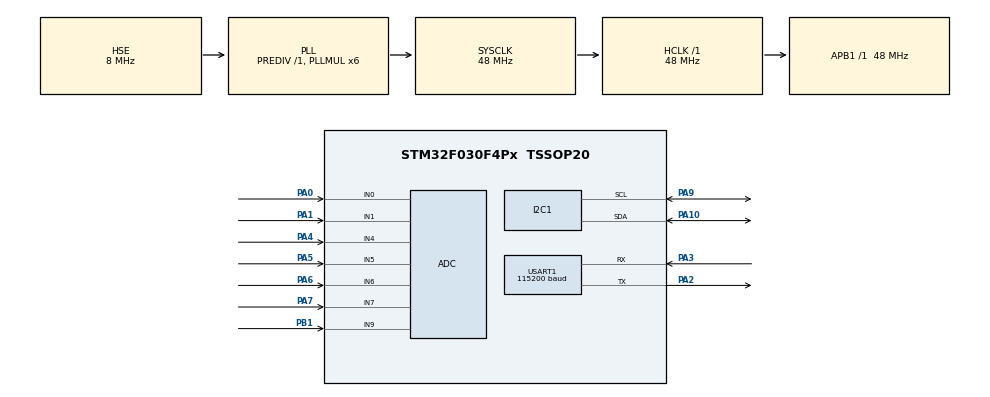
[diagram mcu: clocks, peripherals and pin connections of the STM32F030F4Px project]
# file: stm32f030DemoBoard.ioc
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I2C1.Timing=0x20303E5D
Mcu.Family=STM32F0
Mcu.Name=STM32F030F4Px
Mcu.Package=TSSOP20
NVIC.TIM1_BRK_UP_TRG_COM_IRQn=true\:0\:0\:false\:false\:true\:false
NVIC.TimeBase=TIM1_BRK_UP_TRG_COM_IRQn
NVIC.TimeBaseIP=TIM1
PA0.Mode=IN0
PA0.Signal=ADC_IN0
PA1.Mode=IN1
PA1.Signal=ADC_IN1
PA10.GPIO_FMA10=SYSCFG_CFGR1_I2C_FMP_PA10
PA10.Mode=I2C
PA10.Signal=I2C1_SDA
PA13.Mode=Serial_Wire
PA13.Signal=SYS_SWDIO
PA14.Mode=Serial_Wire
PA14.Signal=SYS_SWCLK
PA2.Mode=Asynchronous
PA2.Signal=USART1_TX
PA3.Mode=Asynchronous
PA3.Signal=USART1_RX
PA4.Mode=IN4
PA4.Signal=ADC_IN4
PA5.Mode=IN5
PA5.Signal=ADC_IN5
PA6.Mode=IN6
PA6.Signal=ADC_IN6
PA7.Mode=IN7
PA7.Signal=ADC_IN7
PA9.GPIO_FMA9=SYSCFG_CFGR1_I2C_FMP_PA9
PA9.Mode=I2C
PA9.Signal=I2C1_SCL
PB1.Mode=IN9
PB1.Signal=ADC_IN9
PF0-OSC_IN.Mode=HSE-External-Oscillator
PF0-OSC_IN.Signal=RCC_OSC_IN
PF1-OSC_OUT.Mode=HSE-External-Oscillator
PF1-OSC_OUT.Signal=RCC_OSC_OUT
ProjectManager.HeapSize=0x200
ProjectManager.StackSize=0x400
ProjectManager.TargetToolchain=MDK-ARM V5
RCC.AHBFreq_Value=48000000
RCC.APB1Freq_Value=48000000
RCC.APB1TimFreq_Value=48000000
RCC.HCLKFreq_Value=48000000
RCC.I2c1ClockSelection=RCC_I2C1CLKSOURCE_SYSCLK
RCC.PLLMUL=RCC_PLL_MUL6
RCC.PLLSourceVirtual=RCC_PLLSOURCE_HSE
RCC.SYSCLKFreq_VALUE=48000000
RCC.SYSCLKSource=RCC_SYSCLKSOURCE_PLLCLK
USART1.BaudRate=115200
USART1.VirtualMode-Asynchronous=VM_ASYNC
VP_ADC_TempSens_Input.Mode=IN-TempSens
VP_ADC_Vref_Input.Mode=IN-Vrefint
VP_RTC_VS_RTC_Activate.Mode=RTC_Enabled
VP_RTC_VS_RTC_Calendar.Mode=RTC_Calendar
VP_SYS_VS_tim1.Mode=TIM1
board=custom

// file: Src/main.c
/**
  ******************************************************************************
  * @file           : main.c
  * @brief          : Main program body
  ******************************************************************************
  ** This notice applies to any and all portions of this file
  * that are not between comment pairs USER CODE BEGIN and
  * USER CODE END. Other portions of this file, whether
  * inserted by the user or by software development tools
  * are owned by their respective copyright owners.
  *
  * COPYRIGHT(c) 2018 STMicroelectronics
  *
  * Redistribution and use in source and binary forms, with or without modification,
  * are permitted provided that the following conditions are met:
  *   1. Redistributions of source code must retain the above copyright notice,
  *      this list of conditions and the following disclaimer.
  *   2. Redistributions in binary form must reproduce the above copyright notice,
  *      this list of conditions and the following disclaimer in the documentation
  *      and/or other materials provided with the distribution.
  *   3. Neither the name of STMicroelectronics nor the names of its contributors
  *      may be used to endorse or promote products derived from this software
  *      without specific prior written permission.
  *
  * THIS SOFTWARE IS PROVIDED BY THE COPYRIGHT HOLDERS AND CONTRIBUTORS "AS IS"
  * AND ANY EXPRESS OR IMPLIED WARRANTIES, INCLUDING, BUT NOT LIMITED TO, THE
  * IMPLIED WARRANTIES OF MERCHANTABILITY AND FITNESS FOR A PARTICULAR PURPOSE ARE
  * DISCLAIMED. IN NO EVENT SHALL THE COPYRIGHT HOLDER OR CONTRIBUTORS BE LIABLE
  * FOR ANY DIRECT, INDIRECT, INCIDENTAL, SPECIAL, EXEMPLARY, OR CONSEQUENTIAL
  * DAMAGES (INCLUDING, BUT NOT LIMITED TO, PROCUREMENT OF SUBSTITUTE GOODS OR
  * SERVICES; LOSS OF USE, DATA, OR PROFITS; OR BUSINESS INTERRUPTION) HOWEVER
  * CAUSED AND ON ANY THEORY OF LIABILITY, WHETHER IN CONTRACT, STRICT LIABILITY,
  * OR TORT (INCLUDING NEGLIGENCE OR OTHERWISE) ARISING IN ANY WAY OUT OF THE USE
  * OF THIS SOFTWARE, EVEN IF ADVISED OF THE POSSIBILITY OF SUCH DAMAGE.
  *
  ******************************************************************************
  */
#include "main.h"
#include "stm32f0xx_hal.h"
// #include "bme280_mod.h"

ADC_HandleTypeDef hadc;
RTC_HandleTypeDef hrtc;
I2C_HandleTypeDef hi2c1;
UART_HandleTypeDef huart1;

/* USER CODE BEGIN PV */
/* Private variables ---------------------------------------------------------*/

#define I2C_ADDRESS (0x76<<1) //  (0x60<<1)
#define IMU_WHO_AM_I 0xC
/* USER CODE END PV */

void SystemClock_Config(void);
static void MX_GPIO_Init(void);
static void MX_I2C1_Init(void);
static void MX_ADC_Init(void);
static void MX_USART1_UART_Init(void);
static void MX_RTC_Init(void);
static void mpl3115a(void);
/* USER CODE BEGIN PFP */
void delay (int a);

int main(void)
{
  HAL_Init();
  SystemClock_Config();
  MX_ADC_Init();
  MX_GPIO_Init();
  MX_USART1_UART_Init();
  MX_RTC_Init();
  MX_I2C1_Init();

	uint8_t reg=0xF7; // pres + temp registers
	I2C_HandleTypeDef hi2c = hi2c1;
	uint16_t DevAddress = I2C_ADDRESS;
	uint16_t MemAddress = 0xf4;// configuration registers 0xf4, 0xf5
	uint16_t MemAddSize = 1;
	uint8_t pData[2] = {0xff,0x10};
	//pData[0] = 3;
	uint16_t Size = 2;
	uint32_t Timeout = 100;
	while(HAL_I2C_IsDeviceReady(&hi2c1, DevAddress, 1, HAL_MAX_DELAY)!=HAL_OK);
	HAL_I2C_Mem_Write(&hi2c, DevAddress, MemAddress, MemAddSize, pData, Size, Timeout);
	while (1)
  {
		HAL_ADC_Start(&hadc);

		HAL_GPIO_WritePin(GPIOA,GPIO_PIN_4,GPIO_PIN_SET);//LED on
		HAL_Delay(50);
		HAL_GPIO_WritePin(GPIOA,GPIO_PIN_4,GPIO_PIN_RESET);//LED off
		if(0) mpl3115a();
		//uint8_t analog0 = HAL_AD
		uint8_t temp[]={0,0,0,0,0,0};
	  while(HAL_I2C_IsDeviceReady(&hi2c1, DevAddress, 1, HAL_MAX_DELAY)!=HAL_OK);
		HAL_I2C_Mem_Read(&hi2c1,I2C_ADDRESS,reg,1,temp,sizeof(temp),1000);
		uint16_t x[] = {0};
		if(HAL_ADC_PollForConversion(&hadc,100)!=HAL_ERROR)
			x[0] = HAL_ADC_GetValue(&hadc);
		for(int j=0; j<sizeof(temp);j++){
				HAL_UART_Transmit(&huart1,&(temp[j]),sizeof(temp[j]),100);
		}
		HAL_ADC_Stop(&hadc);

		//HAL_UART_Transmit(&huart1,(uint8_t *)(x),sizeof(x),100);
		HAL_Delay(20);
		//delay(200000);
  }
}
void mpl3115a(void){	// ------ i2c Polling - no FIFO
		uint8_t reg = 0x0C; //  1. who am i?
		uint8_t val[] = {0,0,0,0,0,0,0};
		while(HAL_I2C_IsDeviceReady(&hi2c1, I2C_ADDRESS, 1, HAL_MAX_DELAY)!=HAL_OK) ;
		HAL_I2C_Mem_Read(&hi2c1, I2C_ADDRESS, reg, I2C_MEMADD_SIZE_8BIT, val, 2, HAL_MAX_DELAY);
		delay(100000);
		while(HAL_I2C_IsDeviceReady(&hi2c1, I2C_ADDRESS, 1, HAL_MAX_DELAY)!=HAL_OK);
		if(1){
			HAL_UART_Transmit(&huart1,&val[0],sizeof(val),1000);
			HAL_UART_Transmit(&huart1,(uint8_t *)"\r\n",sizeof("\r\n"),1000);
		}

		reg = 0x26; //  2. Altimeter to OSR = 128
		uint8_t write[] = {0xB8};
		while(HAL_I2C_IsDeviceReady(&hi2c1, I2C_ADDRESS, 1, HAL_MAX_DELAY)!=HAL_OK);
		HAL_I2C_Mem_Write(&hi2c1, I2C_ADDRESS, reg, I2C_MEMADD_SIZE_8BIT, write, 2, HAL_MAX_DELAY);
		while(HAL_I2C_IsDeviceReady(&hi2c1, I2C_ADDRESS, 1, HAL_MAX_DELAY)!=HAL_OK);

		reg = 0x13; //  3. Enable data flags in PT_DATA_CFG
		write[0] = 0x07;
		while(HAL_I2C_IsDeviceReady(&hi2c1, I2C_ADDRESS, 1, HAL_MAX_DELAY)!=HAL_OK);
		HAL_I2C_Mem_Write(&hi2c1, I2C_ADDRESS, reg, I2C_MEMADD_SIZE_8BIT, write, 2, HAL_MAX_DELAY);
		while(HAL_I2C_IsDeviceReady(&hi2c1, I2C_ADDRESS, 1, HAL_MAX_DELAY)!=HAL_OK);

		reg = 0x26; //  4. Set active
		write[0] = 0xB9;
		while(HAL_I2C_IsDeviceReady(&hi2c1, I2C_ADDRESS, 1, HAL_MAX_DELAY)!=HAL_OK);
		HAL_I2C_Mem_Write(&hi2c1, I2C_ADDRESS, reg, I2C_MEMADD_SIZE_8BIT, write, 2, HAL_MAX_DELAY);
		while(HAL_I2C_IsDeviceReady(&hi2c1, I2C_ADDRESS, 1, HAL_MAX_DELAY)!=HAL_OK);

		while(1){
			val[0]=0;
			reg = 0x0; //  5. Read Status Register + DATA
			// while(HAL_I2C_IsDeviceReady(&hi2c1, I2C_ADDRESS, 1, HAL_MAX_DELAY)!=HAL_OK);
			while(val[0]==0)
				HAL_I2C_Mem_Read(&hi2c1, I2C_ADDRESS, 0x0, I2C_MEMADD_SIZE_8BIT, val, 6, HAL_MAX_DELAY);
			HAL_UART_Transmit(&huart1,val,sizeof(val),1000);
			HAL_UART_Transmit(&huart1,(uint8_t *)"\r\n",sizeof("\r\n"),1000);
			delay(480000);
		}
}
void SystemClock_Config(void)
{

  RCC_OscInitTypeDef RCC_OscInitStruct;
  RCC_ClkInitTypeDef RCC_ClkInitStruct;
  RCC_PeriphCLKInitTypeDef PeriphClkInit;

    /**Initializes the CPU, AHB and APB busses clocks
    */
  RCC_OscInitStruct.OscillatorType = RCC_OSCILLATORTYPE_HSI14|RCC_OSCILLATORTYPE_LSI
                              |RCC_OSCILLATORTYPE_HSE;
  RCC_OscInitStruct.HSEState = RCC_HSE_ON;
  RCC_OscInitStruct.HSI14State = RCC_HSI14_ON;
  RCC_OscInitStruct.HSI14CalibrationValue = 16;
  RCC_OscInitStruct.LSIState = RCC_LSI_ON;
  RCC_OscInitStruct.PLL.PLLState = RCC_PLL_ON;
  RCC_OscInitStruct.PLL.PLLSource = RCC_PLLSOURCE_HSE;
  RCC_OscInitStruct.PLL.PLLMUL = RCC_PLL_MUL6;
  RCC_OscInitStruct.PLL.PREDIV = RCC_PREDIV_DIV1;
  if (HAL_RCC_OscConfig(&RCC_OscInitStruct) != HAL_OK)
  {
    _Error_Handler(__FILE__, __LINE__);
  }

    /**Initializes the CPU, AHB and APB busses clocks
    */
  RCC_ClkInitStruct.ClockType = RCC_CLOCKTYPE_HCLK|RCC_CLOCKTYPE_SYSCLK
                              |RCC_CLOCKTYPE_PCLK1;
  RCC_ClkInitStruct.SYSCLKSource = RCC_SYSCLKSOURCE_PLLCLK;
  RCC_ClkInitStruct.AHBCLKDivider = RCC_SYSCLK_DIV1;
  RCC_ClkInitStruct.APB1CLKDivider = RCC_HCLK_DIV1;

  if (HAL_RCC_ClockConfig(&RCC_ClkInitStruct, FLASH_LATENCY_1) != HAL_OK)
  {
    _Error_Handler(__FILE__, __LINE__);
  }

  PeriphClkInit.PeriphClockSelection = RCC_PERIPHCLK_USART1|RCC_PERIPHCLK_I2C1
                              |RCC_PERIPHCLK_RTC;
  PeriphClkInit.Usart1ClockSelection = RCC_USART1CLKSOURCE_PCLK1;
  PeriphClkInit.I2c1ClockSelection = RCC_I2C1CLKSOURCE_SYSCLK;
  PeriphClkInit.RTCClockSelection = RCC_RTCCLKSOURCE_LSI;
  if (HAL_RCCEx_PeriphCLKConfig(&PeriphClkInit) != HAL_OK)
  {
    _Error_Handler(__FILE__, __LINE__);
  }

    /**Configure the Systick interrupt time
    */
  HAL_SYSTICK_Config(HAL_RCC_GetHCLKFreq()/1000);

    /**Configure the Systick
    */
  HAL_SYSTICK_CLKSourceConfig(SYSTICK_CLKSOURCE_HCLK);

  /* SysTick_IRQn interrupt configuration */
  HAL_NVIC_SetPriority(SysTick_IRQn, 0, 0);
}

/* ADC init function */
static void MX_ADC_Init(void)
{

  ADC_ChannelConfTypeDef sConfig;

    /**Configure the global features of the ADC (Clock, Resolution, Data Alignment and number of conversion)
    */
  hadc.Instance = ADC1;
  hadc.Init.ClockPrescaler = ADC_CLOCK_ASYNC_DIV1;
  hadc.Init.Resolution = ADC_RESOLUTION_12B;
  hadc.Init.DataAlign = ADC_DATAALIGN_RIGHT;
  hadc.Init.ScanConvMode = ADC_SCAN_DIRECTION_FORWARD;
  hadc.Init.EOCSelection = DISABLE;
  hadc.Init.LowPowerAutoWait = DISABLE;
  hadc.Init.LowPowerAutoPowerOff = DISABLE;
  hadc.Init.ContinuousConvMode = DISABLE;
  hadc.Init.DiscontinuousConvMode = DISABLE;
  hadc.Init.ExternalTrigConv = ADC_SOFTWARE_START;
  hadc.Init.ExternalTrigConvEdge = ADC_EXTERNALTRIGCONVEDGE_NONE;
  hadc.Init.DMAContinuousRequests = DISABLE;
  hadc.Init.Overrun = ADC_OVR_DATA_PRESERVED;
  if (HAL_ADC_Init(&hadc) != HAL_OK)
  {
    _Error_Handler(__FILE__, __LINE__);
  }

    /**Configure for the selected ADC regular channel to be converted.
    */
  sConfig.Channel = ADC_CHANNEL_0;
  sConfig.Rank = ADC_RANK_CHANNEL_NUMBER;
  sConfig.SamplingTime = ADC_SAMPLETIME_1CYCLE_5;
  if (HAL_ADC_ConfigChannel(&hadc, &sConfig) != HAL_OK)
  {
    _Error_Handler(__FILE__, __LINE__);
  }

    /**Configure for the selected ADC regular channel to be converted.
    */
  sConfig.Channel = ADC_CHANNEL_1;
  if (HAL_ADC_ConfigChannel(&hadc, &sConfig) != HAL_OK)
  {
    _Error_Handler(__FILE__, __LINE__);
  }

    /**Configure for the selected ADC regular channel to be converted.
    */
//  sConfig.Channel = ADC_CHANNEL_4;
//  if (HAL_ADC_ConfigChannel(&hadc, &sConfig) != HAL_OK)
//  {
//    _Error_Handler(__FILE__, __LINE__);
//  }

    /**Configure for the selected ADC regular channel to be converted.
    */
  sConfig.Channel = ADC_CHANNEL_5;
  if (HAL_ADC_ConfigChannel(&hadc, &sConfig) != HAL_OK)
  {
    _Error_Handler(__FILE__, __LINE__);
  }

    /**Configure for the selected ADC regular channel to be converted.
    */
  sConfig.Channel = ADC_CHANNEL_6;
  if (HAL_ADC_ConfigChannel(&hadc, &sConfig) != HAL_OK)
  {
    _Error_Handler(__FILE__, __LINE__);
  }

    /**Configure for the selected ADC regular channel to be converted.
    */
  sConfig.Channel = ADC_CHANNEL_7;
  if (HAL_ADC_ConfigChannel(&hadc, &sConfig) != HAL_OK)
  {
    _Error_Handler(__FILE__, __LINE__);
  }

    /**Configure for the selected ADC regular channel to be converted.
    */
  sConfig.Channel = ADC_CHANNEL_9;
  if (HAL_ADC_ConfigChannel(&hadc, &sConfig) != HAL_OK)
  {
    _Error_Handler(__FILE__, __LINE__);
  }

    /**Configure for the selected ADC regular channel to be converted.
    */
  sConfig.Channel = ADC_CHANNEL_TEMPSENSOR;
  if (HAL_ADC_ConfigChannel(&hadc, &sConfig) != HAL_OK)
  {
    _Error_Handler(__FILE__, __LINE__);
  }

    /**Configure for the selected ADC regular channel to be converted.
    */
  sConfig.Channel = ADC_CHANNEL_VREFINT;
  if (HAL_ADC_ConfigChannel(&hadc, &sConfig) != HAL_OK)
  {
    _Error_Handler(__FILE__, __LINE__);
  }

}

/* I2C1 init function */
static void MX_I2C1_Init(void)
{

  hi2c1.Instance = I2C1;
  hi2c1.Init.Timing = 0x1303E5D; // 0x20303E5D
  hi2c1.Init.OwnAddress1 = 0;
  hi2c1.Init.AddressingMode = I2C_ADDRESSINGMODE_7BIT;
  hi2c1.Init.DualAddressMode = I2C_DUALADDRESS_DISABLE;
  hi2c1.Init.OwnAddress2 = 0;
  hi2c1.Init.OwnAddress2Masks = I2C_OA2_NOMASK;
  hi2c1.Init.GeneralCallMode = I2C_GENERALCALL_DISABLE;
  hi2c1.Init.NoStretchMode = I2C_NOSTRETCH_DISABLE;
  if (HAL_I2C_Init(&hi2c1) != HAL_OK)
  {
    _Error_Handler(__FILE__, __LINE__);
  }

    /**Configure Analogue filter
    */
  if (HAL_I2CEx_ConfigAnalogFilter(&hi2c1, I2C_ANALOGFILTER_ENABLE) != HAL_OK)
  {
    _Error_Handler(__FILE__, __LINE__);
  }

    /**Configure Digital filter
    */
  if (HAL_I2CEx_ConfigDigitalFilter(&hi2c1, 0) != HAL_OK)
  {
    _Error_Handler(__FILE__, __LINE__);
  }

}

/* RTC init function */
static void MX_RTC_Init(void)
{

  RTC_TimeTypeDef sTime;
  RTC_DateTypeDef sDate;

    /**Initialize RTC Only
    */
  hrtc.Instance = RTC;
  hrtc.Init.HourFormat = RTC_HOURFORMAT_24;
  hrtc.Init.AsynchPrediv = 127;
  hrtc.Init.SynchPrediv = 255;
  hrtc.Init.OutPut = RTC_OUTPUT_DISABLE;
  hrtc.Init.OutPutPolarity = RTC_OUTPUT_POLARITY_HIGH;
  hrtc.Init.OutPutType = RTC_OUTPUT_TYPE_OPENDRAIN;
  if (HAL_RTC_Init(&hrtc) != HAL_OK)
  {
    _Error_Handler(__FILE__, __LINE__);
  }

    /**Initialize RTC and set the Time and Date
    */
  sTime.Hours = 0x0;
  sTime.Minutes = 0x0;
  sTime.Seconds = 0x0;
  sTime.DayLightSaving = RTC_DAYLIGHTSAVING_NONE;
  sTime.StoreOperation = RTC_STOREOPERATION_RESET;
  if (HAL_RTC_SetTime(&hrtc, &sTime, RTC_FORMAT_BCD) != HAL_OK)
  {
    _Error_Handler(__FILE__, __LINE__);
  }

  sDate.WeekDay = RTC_WEEKDAY_MONDAY;
  sDate.Month = RTC_MONTH_JANUARY;
  sDate.Date = 0x1;
  sDate.Year = 0x0;

  if (HAL_RTC_SetDate(&hrtc, &sDate, RTC_FORMAT_BCD) != HAL_OK)
  {
    _Error_Handler(__FILE__, __LINE__);
  }

}

/* USART1 init function */
static void MX_USART1_UART_Init(void)
{

  huart1.Instance = USART1;
  huart1.Init.BaudRate = 115200;
  huart1.Init.WordLength = UART_WORDLENGTH_8B;
  huart1.Init.StopBits = UART_STOPBITS_1;
  huart1.Init.Parity = UART_PARITY_NONE;
  huart1.Init.Mode = UART_MODE_TX_RX;
  huart1.Init.HwFlowCtl = UART_HWCONTROL_NONE;
  huart1.Init.OverSampling = UART_OVERSAMPLING_16;
  huart1.Init.OneBitSampling = UART_ONE_BIT_SAMPLE_DISABLE;
  huart1.AdvancedInit.AdvFeatureInit = UART_ADVFEATURE_NO_INIT;
  if (HAL_UART_Init(&huart1) != HAL_OK)
  {
    _Error_Handler(__FILE__, __LINE__);
  }

}

/** Configure pins as
        * Analog
        * Input
        * Output
        * EVENT_OUT
        * EXTI
*/
static void MX_GPIO_Init(void)
{

  GPIO_InitTypeDef GPIO_InitStruct;

  /* GPIO Ports Clock Enable */
  __HAL_RCC_GPIOF_CLK_ENABLE();
  __HAL_RCC_GPIOA_CLK_ENABLE();
  __HAL_RCC_GPIOB_CLK_ENABLE();

  /*Configure GPIO pin Output Level */
  HAL_GPIO_WritePin(GPIOA, GPIO_PIN_4, GPIO_PIN_RESET);

  /*Configure GPIO pin : PA4 */
  GPIO_InitStruct.Pin = GPIO_PIN_4;
  GPIO_InitStruct.Mode = GPIO_MODE_OUTPUT_PP;
  GPIO_InitStruct.Pull = GPIO_NOPULL;
  GPIO_InitStruct.Speed = GPIO_SPEED_FREQ_LOW;
  HAL_GPIO_Init(GPIOA, &GPIO_InitStruct);
}

/* USER CODE BEGIN 4 */
void delay (int a)
{
    volatile int i,j;

    for (i=0 ; i < a ; i++)
    {
        j++;
    }

    return;
}

/* USER CODE END 4 */

void HAL_TIM_PeriodElapsedCallback(TIM_HandleTypeDef *htim)
{
  if (htim->Instance == TIM1) {
    HAL_IncTick();
  }
}

void _Error_Handler(char *file, int line)
{
  while(1)
  {
  }
}

/************************ (C) COPYRIGHT STMicroelectronics *****END OF FILE****/
